AUTOSAR XML (schema 4-2-2)
package /Components
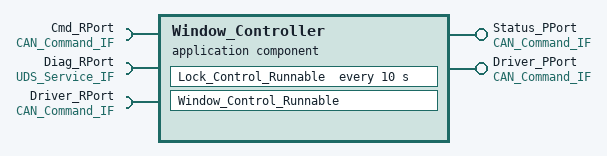
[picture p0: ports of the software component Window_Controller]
  application sw component type Window_Controller
    provide port Status_PPort: provided-interface=CAN_Command_IF
    provide port Driver_PPort: provided-interface=CAN_Command_IF
    require port Cmd_RPort: required-interface=CAN_Command_IF
    require port Diag_RPort: required-interface=UDS_Service_IF
    require port Driver_RPort: required-interface=CAN_Command_IF
    behavior Window_Controller_Behavior
      data received event WindowCmd_Received: start-on-event=Lock_Control_Runnable
      timing event Window_Control_Tick: start-on-event=Lock_Control_Runnable, period=10
      runnable Window_Control_Runnable: minimum-start-interval=10, symbol=Window_Control_Runnable_Symbol
        data-receive-point-by-arguments:
          access WindowCommandAccess: accessed-variable=Cmd_RPort.WindowCommand
        data-send-points:
          access WindowStatusAccess: accessed-variable=Status_PPort.WindowStatus
        sync call MotorDriver_Call: operation=Driver_RPort.SetMotorCmd, timeout=50
